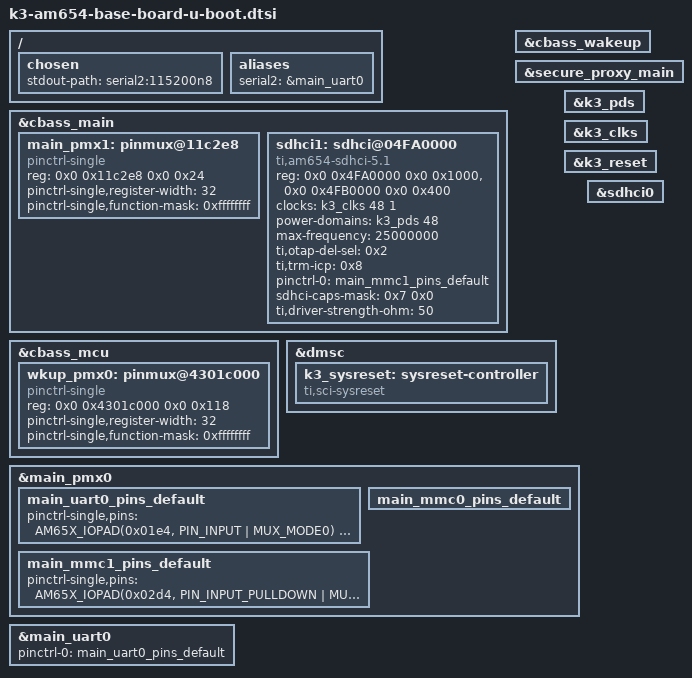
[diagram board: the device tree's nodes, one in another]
// SPDX-License-Identifier: GPL-2.0
/*
 * Copyright (C) 2018 Texas Instruments Incorporated - http://www.ti.com/
 */

#include <dt-bindings/pinctrl/k3-am65.h>

/ {
	chosen {
		stdout-path = "serial2:115200n8";
	};

	aliases {
		serial2 = &main_uart0;
	};
};

&cbass_main{
	u-boot,dm-spl;

	main_pmx1: pinmux@11c2e8 {
		compatible = "pinctrl-single";
		reg = <0x0 0x11c2e8 0x0 0x24>;
		#pinctrl-cells = <1>;
		pinctrl-single,register-width = <32>;
		pinctrl-single,function-mask = <0xffffffff>;
	};

	sdhci1: sdhci@04FA0000 {
		compatible = "ti,am654-sdhci-5.1";
		reg = <0x0 0x4FA0000 0x0 0x1000>,
		      <0x0 0x4FB0000 0x0 0x400>;
		clocks = <&k3_clks 48 1>;
		power-domains = <&k3_pds 48>;
		max-frequency = <25000000>;
		ti,otap-del-sel = <0x2>;
		ti,trm-icp = <0x8>;
	};

};

&cbass_mcu {
	u-boot,dm-spl;
	wkup_pmx0: pinmux@4301c000 {
		compatible = "pinctrl-single";
		reg = <0x0 0x4301c000 0x0 0x118>;
		#pinctrl-cells = <1>;
		pinctrl-single,register-width = <32>;
		pinctrl-single,function-mask = <0xffffffff>;
	};
};

&cbass_wakeup {
	u-boot,dm-spl;
};

&secure_proxy_main {
	u-boot,dm-spl;
};

&dmsc {
	u-boot,dm-spl;
	k3_sysreset: sysreset-controller {
		compatible = "ti,sci-sysreset";
		u-boot,dm-spl;
	};
};

&k3_pds {
	u-boot,dm-spl;
};

&k3_clks {
	u-boot,dm-spl;
};

&k3_reset {
	u-boot,dm-spl;
};

&main_pmx0 {
	u-boot,dm-spl;
	main_uart0_pins_default: main_uart0_pins_default {
		pinctrl-single,pins = <
			AM65X_IOPAD(0x01e4, PIN_INPUT | MUX_MODE0)	/* (AF11) UART0_RXD */
			AM65X_IOPAD(0x01e8, PIN_OUTPUT | MUX_MODE0)	/* (AE11) UART0_TXD */
			AM65X_IOPAD(0x01ec, PIN_INPUT | MUX_MODE0)	/* (AG11) UART0_CTSn */
			AM65X_IOPAD(0x01f0, PIN_OUTPUT | MUX_MODE0)	/* (AD11) UART0_RTSn */
		>;
		u-boot,dm-spl;
	};

	main_mmc0_pins_default: main_mmc0_pins_default {
		u-boot,dm-spl;
	};

	main_mmc1_pins_default: main_mmc1_pins_default {
		pinctrl-single,pins = <
			AM65X_IOPAD(0x02d4, PIN_INPUT_PULLDOWN | MUX_MODE0) /* (C27) MMC1_CLK */
			AM65X_IOPAD(0x02d8, PIN_INPUT_PULLUP | MUX_MODE0) /* (C28) MMC1_CMD */
			AM65X_IOPAD(0x02d0, PIN_INPUT_PULLUP | MUX_MODE0) /* (D28) MMC1_DAT0 */
			AM65X_IOPAD(0x02cc, PIN_INPUT_PULLUP | MUX_MODE0) /* (E27) MMC1_DAT1 */
			AM65X_IOPAD(0x02c8, PIN_INPUT_PULLUP | MUX_MODE0) /* (D26) MMC1_DAT2 */
			AM65X_IOPAD(0x02c4, PIN_INPUT_PULLUP | MUX_MODE0) /* (D27) MMC1_DAT3 */
			AM65X_IOPAD(0x02dc, PIN_INPUT_PULLUP | MUX_MODE0) /* (B24) MMC1_SDCD */
			AM65X_IOPAD(0x02e0, PIN_INPUT | MUX_MODE0) /* (C24) MMC1_SDWP */
		>;
		u-boot,dm-spl;
	};

};

&main_pmx1 {
	u-boot,dm-spl;
};

&main_uart0 {
	u-boot,dm-spl;
	pinctrl-names = "default";
	pinctrl-0 = <&main_uart0_pins_default>;
	status = "okay";
};

&sdhci0 {
	u-boot,dm-spl;
};

&sdhci1 {
	u-boot,dm-spl;
	status = "okay";
	pinctrl-names = "default";
	pinctrl-0 = <&main_mmc1_pins_default>;
	sdhci-caps-mask = <0x7 0x0>;
	ti,driver-strength-ohm = <50>;
};
